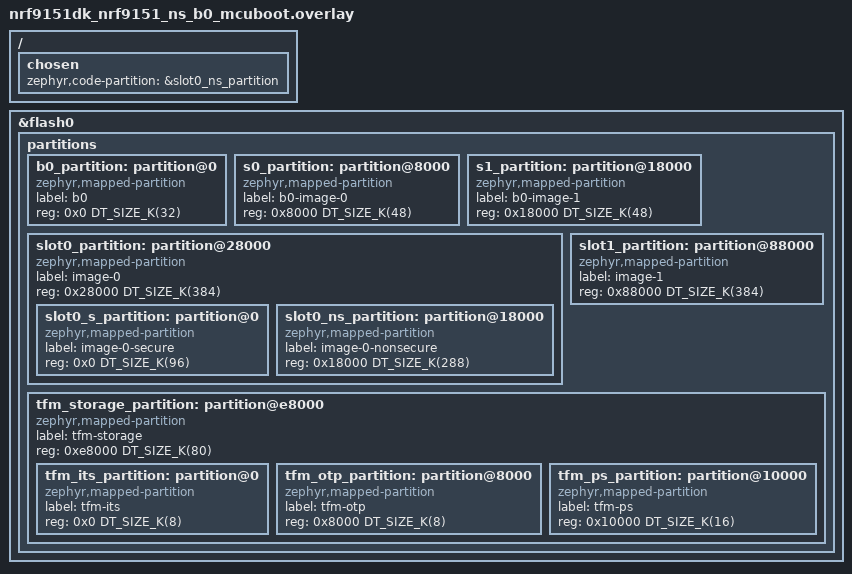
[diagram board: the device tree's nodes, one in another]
/*
 * Copyright (c) 2026 Nordic Semiconductor ASA
 *
 * SPDX-License-Identifier: LicenseRef-Nordic-5-Clause
 */

&flash0 {
	/delete-node/ partitions;

	partitions {
		ranges;
		#address-cells = <1>;
		#size-cells = <1>;

		b0_partition: partition@0 {
			compatible = "zephyr,mapped-partition";
			label = "b0";
			reg = <0x0 DT_SIZE_K(32)>;
		};

		s0_partition: partition@8000 {
			compatible = "zephyr,mapped-partition";
			label = "b0-image-0";
			reg = <0x8000 DT_SIZE_K(48)>;
		};

		s1_partition: partition@18000 {
			compatible = "zephyr,mapped-partition";
			label = "b0-image-1";
			reg = <0x18000 DT_SIZE_K(48)>;
		};

		slot0_partition: partition@28000 {
			compatible = "zephyr,mapped-partition";
			label = "image-0";
			reg = <0x28000 DT_SIZE_K(384)>;
			ranges = <0x0 0x28000 DT_SIZE_K(384)>;
			#address-cells = <1>;
			#size-cells = <1>;

			slot0_s_partition: partition@0 {
				compatible = "zephyr,mapped-partition";
				label = "image-0-secure";
				reg = <0x0 DT_SIZE_K(96)>;
			};

			slot0_ns_partition: partition@18000 {
				compatible = "zephyr,mapped-partition";
				label = "image-0-nonsecure";
				reg = <0x18000 DT_SIZE_K(288)>;
			};
		};

		slot1_partition: partition@88000 {
			compatible = "zephyr,mapped-partition";
			label = "image-1";
			reg = <0x88000 DT_SIZE_K(384)>;
		};

		tfm_storage_partition: partition@e8000 {
			compatible = "zephyr,mapped-partition";
			label = "tfm-storage";
			reg = <0xe8000 DT_SIZE_K(80)>;
			ranges = <0x0 0xe8000 DT_SIZE_K(80)>;
			#address-cells = <1>;
			#size-cells = <1>;

			tfm_its_partition: partition@0 {
				compatible = "zephyr,mapped-partition";
				label = "tfm-its";
				reg = <0x0 DT_SIZE_K(8)>;
			};

			tfm_otp_partition: partition@8000 {
				compatible = "zephyr,mapped-partition";
				label = "tfm-otp";
				reg = <0x8000 DT_SIZE_K(8)>;
			};

			tfm_ps_partition: partition@10000 {
				compatible = "zephyr,mapped-partition";
				label = "tfm-ps";
				reg = <0x10000 DT_SIZE_K(16)>;
			};
		};
	};
};

/ {
	chosen {
		zephyr,code-partition = &slot0_ns_partition;
	};
};
